AUTOSAR XML (schema 00050)
package /ComponentTypes
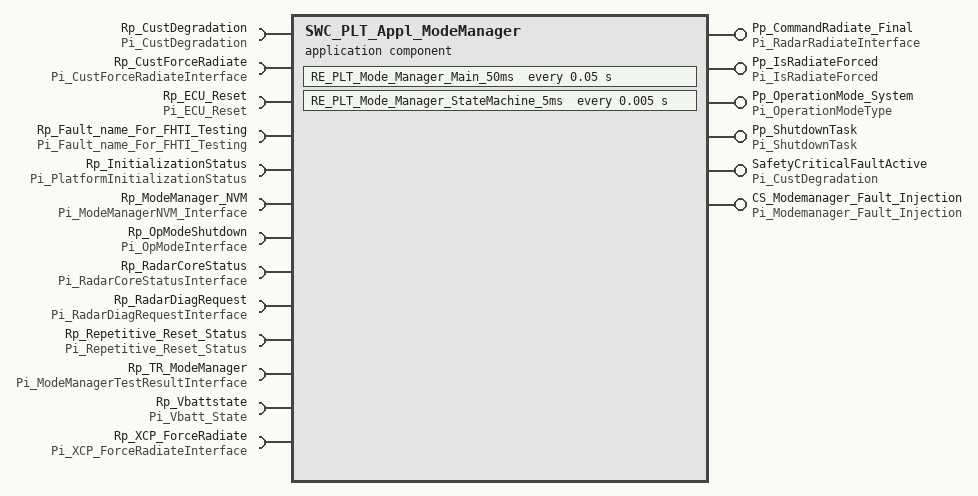
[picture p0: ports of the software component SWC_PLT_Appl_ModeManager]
  application sw component type SWC_PLT_Appl_ModeManager
    5 x provide port:
      Pp_CommandRadiate_Final: nonqueued-sender-com-spec{data-element=De_CommandRadiate_Final, init-value=constant-reference=C_Command_Radiate_Final_T}, provided-interface=Pi_RadarRadiateInterface
      Pp_IsRadiateForced: nonqueued-sender-com-spec{data-element=De_IsRadiateForced, init-value=constant-reference=C_IsRadiateForced_T}, provided-interface=Pi_IsRadiateForced
      Pp_OperationMode_System: nonqueued-sender-com-spec{data-element=De_OperationMode_System, init-value=0}, provided-interface=Pi_OperationModeType
      Pp_ShutdownTask: nonqueued-sender-com-spec{data-element=De_shutdownTask, init-value=85}, provided-interface=Pi_ShutdownTask
      SafetyCriticalFaultActive: nonqueued-sender-com-spec=De_CustDegradation, provided-interface=Pi_CustDegradation
    13 x require port:
      Rp_CustDegradation: nonqueued-receiver-com-spec{data-element=De_CustDegradation, filter=data-filter-type=ALWAYS, init-value=constant-reference=C_CustDegradation}, required-interface=Pi_CustDegradation
      Rp_CustForceRadiate: nonqueued-receiver-com-spec{data-element=CustForceRadiate, filter=data-filter-type=ALWAYS, init-value=constant-reference=C_Force_Radiate_Init_T}, required-interface=Pi_CustForceRadiateInterface
      Rp_ECU_Reset: client-com-spec=ECU_Soft_Reset, required-interface=Pi_ECU_Reset
      Rp_Fault_name_For_FHTI_Testing: nonqueued-receiver-com-spec{data-element=De_Fault_name_FHTI, filter=data-filter-type=ALWAYS, init-value=0}, required-interface=Pi_Fault_name_For_FHTI_Testing
      Rp_InitializationStatus: nonqueued-receiver-com-spec{data-element=De_MCU_InitializationStatus, filter=data-filter-type=ALWAYS, init-value=constant-reference=C_MCU_initlaisation_NOTCompleted_T}, required-interface=Pi_PlatformInitializationStatus
      Rp_ModeManager_NVM: nonqueued-receiver-com-spec{data-element=ModeManager_NVM, filter=data-filter-type=ALWAYS, init-value=constant-reference=C_K_Force_Radiate_Init_T}, required-interface=Pi_ModeManagerNVM_Interface
      Rp_OpModeShutdown: nonqueued-receiver-com-spec{data-element=De_OpModeShutdown, filter=data-filter-type=ALWAYS, init-value=constant-reference=C_OpModeShutdown_init_T}, required-interface=Pi_OpModeInterface
      Rp_RadarCoreStatus: nonqueued-receiver-com-spec{data-element=De_RadarCoreStatus, filter=data-filter-type=ALWAYS, init-value=constant-reference=C_RadarCoreStatus_T}, required-interface=Pi_RadarCoreStatusInterface
      Rp_RadarDiagRequest: nonqueued-receiver-com-spec{data-element=De_RadarDiagRequest, filter=data-filter-type=ALWAYS, init-value=constant-reference=C_RadarDiagRequest_T}, required-interface=Pi_RadarDiagRequestInterface
      Rp_Repetitive_Reset_Status: nonqueued-receiver-com-spec{data-element=De_Repetitive_Reset_Status, filter=data-filter-type=ALWAYS, init-value=85}, required-interface=Pi_Repetitive_Reset_Status
      Rp_TR_ModeManager: nonqueued-receiver-com-spec{data-element=De_TR_ModeManager, filter=data-filter-type=ALWAYS, init-value=constant-reference=C_TR_ModeManager_T}, required-interface=Pi_ModeManagerTestResultInterface
      Rp_Vbattstate: nonqueued-receiver-com-spec{data-element=De_Vbatt_State, filter=data-filter-type=ALWAYS, init-value=0}, required-interface=Pi_Vbatt_State
      Rp_XCP_ForceRadiate: nonqueued-receiver-com-spec{data-element=De_XCPForceRadiate, filter=data-filter-type=ALWAYS, init-value=constant-reference=C_Force_Radiate_Init_T}, required-interface=Pi_XCP_ForceRadiateInterface
    provide port CS_Modemanager_Fault_Injection: server-com-spec{operation=Read, queue-length=1}, provided-interface=Pi_Modemanager_Fault_Injection
    behavior SWC_PLT_Appl_ModeManager_InternalBehavior: handle-termination-and-restart=NO-SUPPORT
      init event SWC_PLT_Appl_ModeManager_InitEvent: start-on-event=RE_PLT_Mode_Manager_Init
      timing event TMT_RE_Platform_ModeManager_Main_50ms: start-on-event=RE_PLT_Mode_Manager_Main_50ms, period=0.05
      timing event TMT_RE_Platform_ModeManagerStateMachine_5ms: start-on-event=RE_PLT_Mode_Manager_StateMachine_5ms, period=0.005
      operation invoked event OIT_CS_Modemanager_Fault_Injection_Read_CS_Modemanager_Fault_Injection_Read: start-on-event=CS_Modemanager_Fault_Injection_Read, operation=CS_Modemanager_Fault_Injection.Read
      4 x runnable:
        RE_PLT_Mode_Manager_Init
          data-receive-point-by-arguments:
            access REC_Rp_Fault_name_For_FHTI_Testing_De_Fault_name_FHTI: accessed-variable=Rp_Fault_name_For_FHTI_Testing.De_Fault_name_FHTI
        RE_PLT_Mode_Manager_Main_50ms
        RE_PLT_Mode_Manager_StateMachine_5ms
          data-receive-point-by-arguments:
            11 x access:
              REC_Rp_CustDegradation_De_CustDegradation: accessed-variable=Rp_CustDegradation.De_CustDegradation
              REC_Rp_CustForceRadiate_CustForceRadiate: accessed-variable=Rp_CustForceRadiate.CustForceRadiate
              REC_Rp_InitializationStatus_De_MCU_InitializationStatus: accessed-variable=Rp_InitializationStatus.De_MCU_InitializationStatus
              REC_Rp_ModeManager_NVM_ModeManager_NVM: accessed-variable=Rp_ModeManager_NVM.ModeManager_NVM
              REC_Rp_OpModeShutdown_De_OpModeShutdown: accessed-variable=Rp_OpModeShutdown.De_OpModeShutdown
              REC_Rp_RadarCoreStatus_De_RadarCoreStatus: accessed-variable=Rp_RadarCoreStatus.De_RadarCoreStatus
              REC_Rp_RadarDiagRequest_De_RadarDiagRequest: accessed-variable=Rp_RadarDiagRequest.De_RadarDiagRequest
              REC_Rp_Repetitive_Reset_Status_De_Repetitive_Reset_Status: accessed-variable=Rp_Repetitive_Reset_Status.De_Repetitive_Reset_Status
              REC_Rp_TR_ModeManager_De_TR_ModeManager: accessed-variable=Rp_TR_ModeManager.De_TR_ModeManager
              REC_Rp_Vbattstate_De_Vbatt_State: accessed-variable=Rp_Vbattstate.De_Vbatt_State
              REC_Rp_XCP_ForceRadiateInterface_XCPForceRadiate: accessed-variable=Rp_XCP_ForceRadiate.De_XCPForceRadiate
          data-send-points:
            4 x access:
              SEND_Pp_CommandRadiate_Final_CommandRadiate_Final: accessed-variable=Pp_CommandRadiate_Final.De_CommandRadiate_Final
              SEND_Pp_IsRadiateForced_De_IsRadiateForced: accessed-variable=Pp_IsRadiateForced.De_IsRadiateForced
              SEND_Pp_OperationMode_System_De_OperationMode_System: accessed-variable=Pp_OperationMode_System.De_OperationMode_System
              SEND_Pp_ShutdownTask_De_ShutdownTask: accessed-variable=Pp_ShutdownTask.De_shutdownTask
          sync call SC_Rp_ECU_Reset_Operation: operation=Rp_ECU_Reset.ECU_Soft_Reset
        CS_Modemanager_Fault_Injection_Read
  swc implementation SWC_PLT_Appl_ModeManager_Implementation: behavior=SWC_PLT_Appl_ModeManager_InternalBehavior
    code-descriptors:
      code Default: artifact-descriptors=autosar-engineering-object=category=SWSRC
